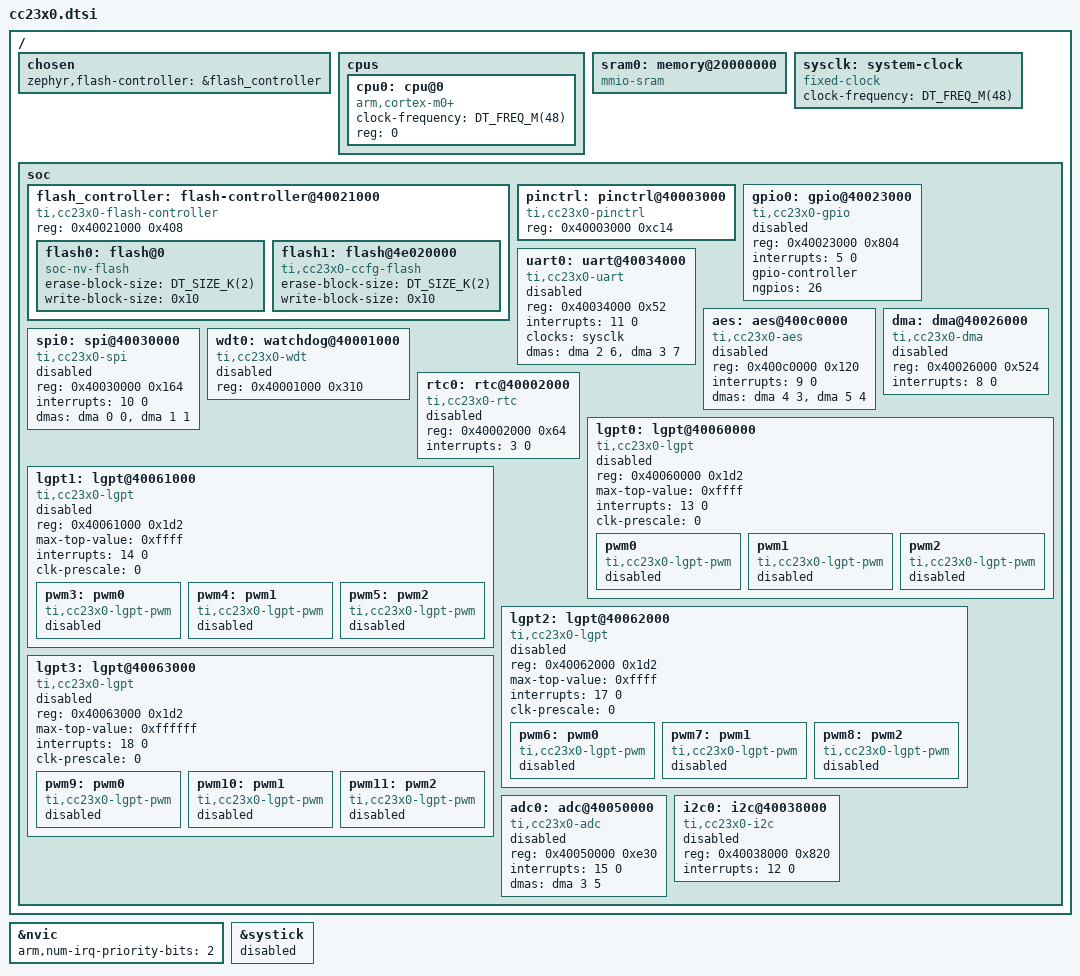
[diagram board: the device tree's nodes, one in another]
/*
 * Copyright (c) 2024 Texas Instruments Incorporated
 * Copyright (c) 2024 BayLibre, SAS
 *
 * SPDX-License-Identifier: Apache-2.0
 */

#include <arm/armv6-m.dtsi>
#include <freq.h>

/ {
	chosen {
		zephyr,flash-controller = &flash_controller;
	};

	cpus {
		#address-cells = <1>;
		#size-cells = <0>;

		cpu0: cpu@0 {
			device_type = "cpu";
			compatible = "arm,cortex-m0+";
			clock-frequency = <DT_FREQ_M(48)>;
			reg = <0>;
		};
	};

	sram0: memory@20000000 {
		compatible = "mmio-sram";
	};

	sysclk: system-clock {
		compatible = "fixed-clock";
		clock-frequency = <DT_FREQ_M(48)>;
		#clock-cells = <0>;
	};

	soc {
		flash_controller: flash-controller@40021000 {
			compatible = "ti,cc23x0-flash-controller";
			reg = <0x40021000 0x408>;
			#address-cells = <1>;
			#size-cells = <1>;

			/* Main flash sector */
			flash0: flash@0 {
				compatible = "soc-nv-flash";
				erase-block-size = <DT_SIZE_K(2)>;
				write-block-size = <0x10>;
			};

			/* CCFG flash sector */
			flash1: flash@4e020000 {
				compatible = "ti,cc23x0-ccfg-flash", "soc-nv-flash";
				erase-block-size = <DT_SIZE_K(2)>;
				write-block-size = <0x10>;
			};
		};

		pinctrl: pinctrl@40003000 {
			compatible = "ti,cc23x0-pinctrl";
			reg = <0x40003000 0xc14>;
		};

		gpio0: gpio@40023000 {
			compatible = "ti,cc23x0-gpio";
			reg = <0x40023000 0x804>;
			interrupts = <5 0>;	/* GPIO combined on CPUIRQ5 */
			status = "disabled";
			gpio-controller;
			#gpio-cells = <2>;	/* Pin (ID), and flags */
			ngpios = <26>;		/* Only [DIO0, DIO25] are available */
		};

		uart0: uart@40034000 {
			compatible = "ti,cc23x0-uart";
			reg = <0x40034000 0x52>;
			interrupts = <11 0>;
			clocks = <&sysclk>;
			dmas = <&dma 2 6>, <&dma 3 7>;
			dma-names = "tx", "rx";
			status = "disabled";
		};

		aes: aes@400c0000 {
			compatible = "ti,cc23x0-aes";
			reg = <0x400c0000 0x120>;
			interrupts = <9 0>;
			dmas = <&dma 4 3>, <&dma 5 4>;
			dma-names = "cha", "chb";
			status = "disabled";
		};

		dma: dma@40026000 {
			compatible = "ti,cc23x0-dma";
			reg = <0x40026000 0x524>;
			interrupts = <8 0>;
			#dma-cells = <2>;
			status = "disabled";
		};

		spi0: spi@40030000 {
			compatible = "ti,cc23x0-spi";
			#address-cells = <1>;
			#size-cells = <0>;
			reg = <0x40030000 0x164>;
			interrupts = <10 0>;
			dmas = <&dma 0 0>, <&dma 1 1>;
			dma-names = "tx", "rx";
			status = "disabled";
		};

		wdt0: watchdog@40001000 {
			compatible = "ti,cc23x0-wdt";
			reg = <0x40001000 0x310>;
			status = "disabled";
		};

		rtc0: rtc@40002000 {
			compatible = "ti,cc23x0-rtc";
			reg = <0x40002000 0x64>;
			interrupts = <3 0>;
			status = "disabled";
		};

		lgpt0: lgpt@40060000 {
			compatible = "ti,cc23x0-lgpt";
			reg = <0x40060000 0x1d2>;
			max-top-value = <0xffff>;
			interrupts = <13 0>;
			clk-prescale = <0>;
			status = "disabled";

			pwm0: pwm0 {
				compatible = "ti,cc23x0-lgpt-pwm";
				#pwm-cells = <3>;
				status = "disabled";
			};

			pwm1: pwm1 {
				compatible = "ti,cc23x0-lgpt-pwm";
				#pwm-cells = <3>;
				status = "disabled";
			};

			pwm2: pwm2 {
				compatible = "ti,cc23x0-lgpt-pwm";
				#pwm-cells = <3>;
				status = "disabled";
			};
		};

		lgpt1: lgpt@40061000 {
			compatible = "ti,cc23x0-lgpt";
			reg = <0x40061000 0x1d2>;
			max-top-value = <0xffff>;
			interrupts = <14 0>;
			clk-prescale = <0>;
			status = "disabled";

			pwm3: pwm0 {
				compatible = "ti,cc23x0-lgpt-pwm";
				#pwm-cells = <3>;
				status = "disabled";
			};

			pwm4: pwm1 {
				compatible = "ti,cc23x0-lgpt-pwm";
				#pwm-cells = <3>;
				status = "disabled";
			};

			pwm5: pwm2 {
				compatible = "ti,cc23x0-lgpt-pwm";
				#pwm-cells = <3>;
				status = "disabled";
			};
		};

		lgpt2: lgpt@40062000 {
			compatible = "ti,cc23x0-lgpt";
			reg = <0x40062000 0x1d2>;
			max-top-value = <0xffff>;
			interrupts = <17 0>;
			clk-prescale = <0>;
			status = "disabled";

			pwm6: pwm0 {
				compatible = "ti,cc23x0-lgpt-pwm";
				#pwm-cells = <3>;
				status = "disabled";
			};

			pwm7: pwm1 {
				compatible = "ti,cc23x0-lgpt-pwm";
				#pwm-cells = <3>;
				status = "disabled";
			};

			pwm8: pwm2 {
				compatible = "ti,cc23x0-lgpt-pwm";
				#pwm-cells = <3>;
				status = "disabled";
			};
		};

		lgpt3: lgpt@40063000 {
			compatible = "ti,cc23x0-lgpt";
			reg = <0x40063000 0x1d2>;
			max-top-value = <0xffffff>;
			interrupts = <18 0>;
			clk-prescale = <0>;
			status = "disabled";

			pwm9: pwm0 {
				compatible = "ti,cc23x0-lgpt-pwm";
				#pwm-cells = <3>;
				status = "disabled";
			};

			pwm10: pwm1 {
				compatible = "ti,cc23x0-lgpt-pwm";
				#pwm-cells = <3>;
				status = "disabled";
			};

			pwm11: pwm2 {
				compatible = "ti,cc23x0-lgpt-pwm";
				#pwm-cells = <3>;
				status = "disabled";
			};
		};

		adc0: adc@40050000 {
			compatible = "ti,cc23x0-adc";
			reg = <0x40050000 0xe30>;
			interrupts = <15 0>;
			#io-channel-cells = <1>;
			dmas = <&dma 3 5>;
			dma-names = "dma";
			status = "disabled";
		};

		i2c0: i2c@40038000 {
			compatible = "ti,cc23x0-i2c";
			#address-cells = <1>;
			#size-cells = <0>;
			reg = <0x40038000 0x820>;
			interrupts = <12 0>;
			status = "disabled";
		};
	};
};

&nvic {
	arm,num-irq-priority-bits = <2>; /* Interrupt levels are 0-192 in steps of 64 */
};

&systick {
	status = "disabled";
};
